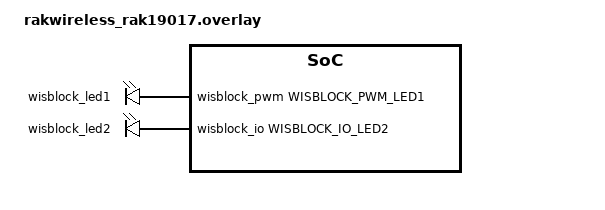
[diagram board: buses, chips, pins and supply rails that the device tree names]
/*
 * SPDX-License-Identifier: Apache-2.0
 * Copyright (c) 2026 Shenzhen RAKwireless Technology Co., Ltd.
 */

#include <zephyr/dt-bindings/gpio/gpio.h>
#include <zephyr/dt-bindings/gpio/wisblock-io-connector.h>
#include <zephyr/dt-bindings/pwm/pwm.h>
#include <zephyr/dt-bindings/pwm/wisblock-pwm.h>

/ {
	rak19017_pwm_leds {
		compatible = "pwm-leds";

		wisblock_led1: rak19017_led1 {
			pwms = <&wisblock_pwm WISBLOCK_PWM_LED1 PWM_MSEC(5) PWM_POLARITY_NORMAL>;
		};
	};

	rak19017_gpio_leds {
		compatible = "gpio-leds";

		wisblock_led2: rak19017_led2 {
			gpios = <&wisblock_io WISBLOCK_IO_LED2 GPIO_ACTIVE_HIGH>;
		};
	};
};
